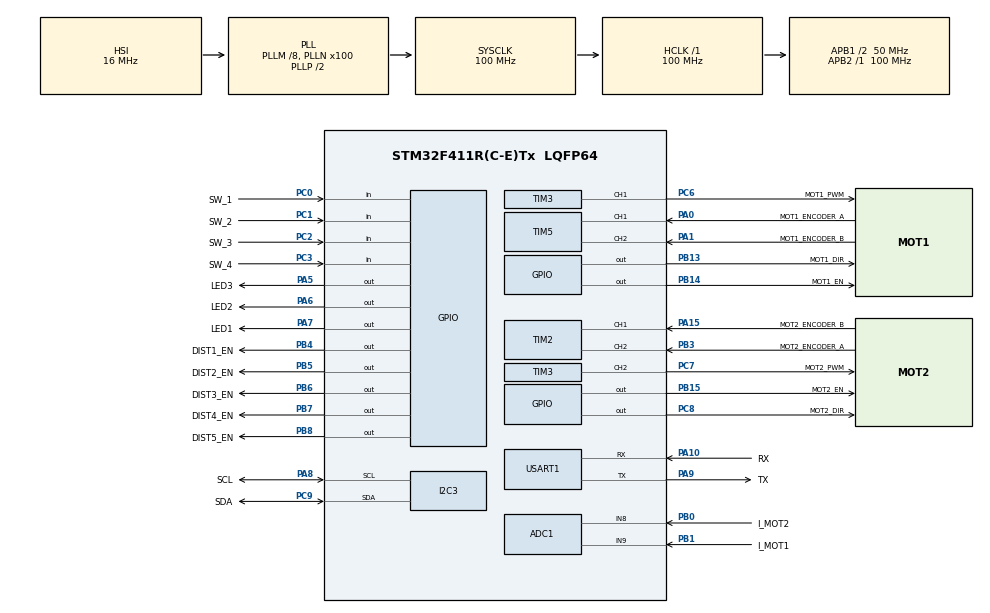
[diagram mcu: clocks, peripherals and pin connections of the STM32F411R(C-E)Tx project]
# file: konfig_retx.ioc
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ADC1.Channel-0\#ChannelRegularConversion=ADC_CHANNEL_8
ADC1.NbrOfConversionFlag=1
ADC1.Rank-0\#ChannelRegularConversion=1
ADC1.SamplingTime-0\#ChannelRegularConversion=ADC_SAMPLETIME_3CYCLES
ADC1.master=1
Mcu.Family=STM32F4
Mcu.Name=STM32F411R(C-E)Tx
Mcu.Package=LQFP64
NVIC.PriorityGroup=NVIC_PRIORITYGROUP_4
NVIC.USART1_IRQn=true\:0\:0\:false\:false\:true\:true\:true
PA0-WKUP.GPIO_Label=MOT1_ENCODER_A
PA0-WKUP.Signal=S_TIM5_CH1
PA1.GPIO_Label=MOT1_ENCODER_B
PA1.Signal=S_TIM5_CH2
PA10.GPIO_Label=RX
PA10.Mode=Asynchronous
PA10.Signal=USART1_RX
PA13.Mode=Serial_Wire
PA13.Signal=SYS_JTMS-SWDIO
PA14.Mode=Serial_Wire
PA14.Signal=SYS_JTCK-SWCLK
PA15.GPIO_Label=MOT2_ENCODER_B
PA15.Signal=S_TIM2_CH1_ETR
PA5.GPIO_Label=LED3
PA5.Signal=GPIO_Output
PA6.GPIO_Label=LED2
PA6.Signal=GPIO_Output
PA7.GPIO_Label=LED1
PA7.Signal=GPIO_Output
PA8.GPIO_Label=SCL
PA8.Mode=I2C
PA8.Signal=I2C3_SCL
PA9.GPIO_Label=TX
PA9.Mode=Asynchronous
PA9.Signal=USART1_TX
PB0.GPIO_Label=I_MOT2
PB0.Signal=ADCx_IN8
PB1.GPIO_Label=I_MOT1
PB1.Signal=ADCx_IN9
PB13.GPIO_Label=MOT1_DIR
PB13.Signal=GPIO_Output
PB14.GPIO_Label=MOT1_EN
PB14.Signal=GPIO_Output
PB15.GPIO_Label=MOT2_EN
PB15.Signal=GPIO_Output
PB3.GPIO_Label=MOT2_ENCODER_A
PB3.Signal=S_TIM2_CH2
PB4.GPIO_Label=DIST1_EN
PB4.Signal=GPIO_Output
PB5.GPIO_Label=DIST2_EN
PB5.Signal=GPIO_Output
PB6.GPIO_Label=DIST3_EN
PB6.Signal=GPIO_Output
PB7.GPIO_Label=DIST4_EN
PB7.Signal=GPIO_Output
PB8.GPIO_Label=DIST5_EN
PB8.Signal=GPIO_Output
PC0.GPIO_Label=SW_1
PC0.Signal=GPIO_Input
PC1.GPIO_Label=SW_2
PC1.Signal=GPIO_Input
PC2.GPIO_Label=SW_3
PC2.Signal=GPIO_Input
PC3.GPIO_Label=SW_4
PC3.Signal=GPIO_Input
PC6.GPIO_Label=MOT1_PWM
PC6.Signal=S_TIM3_CH1
PC7.GPIO_Label=MOT2_PWM
PC7.Signal=S_TIM3_CH2
PC8.GPIO_Label=MOT2_DIR
PC8.Signal=GPIO_Output
PC9.GPIO_Label=SDA
PC9.Mode=I2C
PC9.Signal=I2C3_SDA
PH0\ -\ OSC_IN.Mode=HSE-External-Oscillator
PH0\ -\ OSC_IN.Signal=RCC_OSC_IN
PH1\ -\ OSC_OUT.Mode=HSE-External-Oscillator
PH1\ -\ OSC_OUT.Signal=RCC_OSC_OUT
ProjectManager.HeapSize=0x200
ProjectManager.StackSize=0x400
ProjectManager.TargetToolchain=TrueSTUDIO
RCC.48MHZClocksFreq_Value=50000000
RCC.AHBFreq_Value=100000000
RCC.APB1CLKDivider=RCC_HCLK_DIV2
RCC.APB1Freq_Value=50000000
RCC.APB1TimFreq_Value=100000000
RCC.APB2Freq_Value=100000000
RCC.APB2TimFreq_Value=100000000
RCC.CortexFreq_Value=100000000
RCC.HCLKFreq_Value=100000000
RCC.HSE_VALUE=16000000
RCC.HSI_VALUE=16000000
RCC.LSE_VALUE=32768
RCC.PLLM=8
RCC.PLLN=100
RCC.PLLSourceVirtual=RCC_PLLSOURCE_HSE
RCC.SYSCLKFreq_VALUE=100000000
RCC.SYSCLKSource=RCC_SYSCLKSOURCE_PLLCLK
RCC.VCOOutputFreq_Value=200000000
SH.ADCx_IN8.0=ADC1_IN8,IN8
SH.ADCx_IN9.0=ADC1_IN9,IN9
SH.S_TIM2_CH1_ETR.0=TIM2_CH1,Encoder_Interface
SH.S_TIM2_CH2.0=TIM2_CH2,Encoder_Interface
SH.S_TIM3_CH1.0=TIM3_CH1,PWM Generation1 CH1
SH.S_TIM3_CH2.0=TIM3_CH2,PWM Generation2 CH2
SH.S_TIM5_CH1.0=TIM5_CH1,Encoder_Interface
SH.S_TIM5_CH2.0=TIM5_CH2,Encoder_Interface
TIM3.Channel-PWM\ Generation1\ CH1=TIM_CHANNEL_1
TIM3.Channel-PWM\ Generation2\ CH2=TIM_CHANNEL_2
USART1.VirtualMode=VM_ASYNC
VP_TIM10_VS_ClockSourceINT.Mode=Enable_Timer
VP_TIM11_VS_ClockSourceINT.Mode=Enable_Timer
board=custom

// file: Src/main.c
/* USER CODE BEGIN Header */
/**
  ******************************************************************************
  * @file           : main.c
  * @brief          : Main program body
  ******************************************************************************
  * @attention
  *
  * <h2><center>&copy; Copyright (c) 2020 STMicroelectronics.
  * All rights reserved.</center></h2>
  *
  * This software component is licensed by ST under BSD 3-Clause license,
  * the "License"; You may not use this file except in compliance with the
  * License. You may obtain a copy of the License at:
  *                        opensource.org/licenses/BSD-3-Clause
  *
  ******************************************************************************
  */
/* USER CODE END Header */

#include "main.h"
#include "adc.h"
#include "i2c.h"
#include "tim.h"
#include "usart.h"
#include "gpio.h"

void SystemClock_Config(void);

int main(void)
{

  /* MCU Configuration--------------------------------------------------------*/

  /* Reset of all peripherals, Initializes the Flash interface and the Systick. */
  HAL_Init();

  /* Configure the system clock */
  SystemClock_Config();

  /* Initialize all configured peripherals */
  MX_GPIO_Init();
  MX_USART1_UART_Init();
  MX_TIM2_Init();
  MX_TIM5_Init();
  MX_ADC1_Init();
  MX_I2C3_Init();
  MX_TIM3_Init();
  MX_TIM11_Init();
  MX_TIM10_Init();
  /* USER CODE BEGIN 2 */
  char* wiad="CZESC SWIAT!";
  /* USER CODE END 2 */

  /* Infinite loop */
  /* USER CODE BEGIN WHILE */
  while (1)
  {
	  HAL_GPIO_WritePin(LED1_GPIO_Port,LED1_Pin,GPIO_PIN_RESET);
	  HAL_Delay(333);
	  HAL_UART_Transmit_IT(&huart1,wiad,13);
	  HAL_GPIO_WritePin(LED1_GPIO_Port,LED1_Pin,GPIO_PIN_SET);
	  HAL_Delay(333);
    /* USER CODE END WHILE */

  }
}

void SystemClock_Config(void)
{
  RCC_OscInitTypeDef RCC_OscInitStruct = {0};
  RCC_ClkInitTypeDef RCC_ClkInitStruct = {0};

  /** Configure the main internal regulator output voltage
  */
  __HAL_RCC_PWR_CLK_ENABLE();
  __HAL_PWR_VOLTAGESCALING_CONFIG(PWR_REGULATOR_VOLTAGE_SCALE1);
  /** Initializes the CPU, AHB and APB busses clocks
  */
  RCC_OscInitStruct.OscillatorType = RCC_OSCILLATORTYPE_HSI;
  RCC_OscInitStruct.HSIState = RCC_HSI_ON;
  RCC_OscInitStruct.HSICalibrationValue = RCC_HSICALIBRATION_DEFAULT;
  RCC_OscInitStruct.PLL.PLLState = RCC_PLL_ON;
  RCC_OscInitStruct.PLL.PLLSource = RCC_PLLSOURCE_HSI;
  RCC_OscInitStruct.PLL.PLLM = 8;
  RCC_OscInitStruct.PLL.PLLN = 100;
  RCC_OscInitStruct.PLL.PLLP = RCC_PLLP_DIV2;
  RCC_OscInitStruct.PLL.PLLQ = 4;
  if (HAL_RCC_OscConfig(&RCC_OscInitStruct) != HAL_OK)
  {
    Error_Handler();
  }
  /** Initializes the CPU, AHB and APB busses clocks
  */
  RCC_ClkInitStruct.ClockType = RCC_CLOCKTYPE_HCLK|RCC_CLOCKTYPE_SYSCLK
                              |RCC_CLOCKTYPE_PCLK1|RCC_CLOCKTYPE_PCLK2;
  RCC_ClkInitStruct.SYSCLKSource = RCC_SYSCLKSOURCE_PLLCLK;
  RCC_ClkInitStruct.AHBCLKDivider = RCC_SYSCLK_DIV1;
  RCC_ClkInitStruct.APB1CLKDivider = RCC_HCLK_DIV2;
  RCC_ClkInitStruct.APB2CLKDivider = RCC_HCLK_DIV1;

  if (HAL_RCC_ClockConfig(&RCC_ClkInitStruct, FLASH_LATENCY_3) != HAL_OK)
  {
    Error_Handler();
  }
}

void Error_Handler(void)
{
}

/************************ (C) COPYRIGHT STMicroelectronics *****END OF FILE****/
